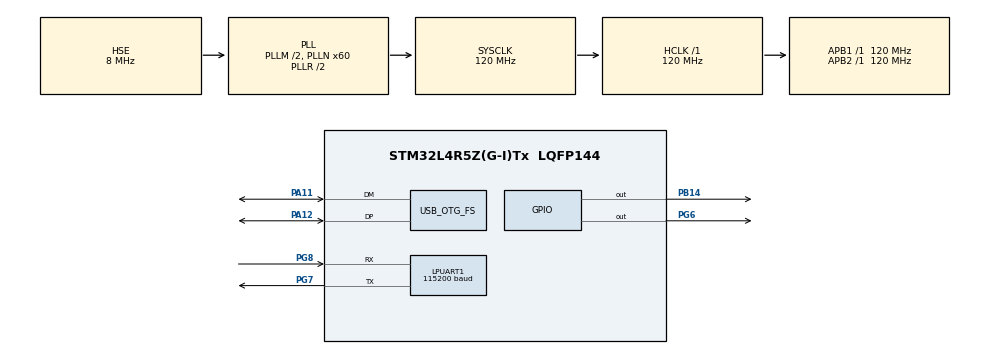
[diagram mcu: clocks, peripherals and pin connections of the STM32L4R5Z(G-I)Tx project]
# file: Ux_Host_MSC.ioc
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LPUART1.BaudRate=115200
LPUART1.WordLength=UART_WORDLENGTH_8B
Mcu.Family=STM32L4
Mcu.Name=STM32L4R5Z(G-I)Tx
Mcu.Package=LQFP144
NVIC.OTG_FS_IRQn=true\:7\:0\:true\:false\:true\:true\:true\:true\:true
NVIC.PriorityGroup=NVIC_PRIORITYGROUP_4
NVIC.TIM6_DAC_IRQn=true\:15\:0\:true\:false\:true\:false\:false\:true\:true
NVIC.TimeBase=TIM6_DAC_IRQn
NVIC.TimeBaseIP=TIM6
PA11.Mode=Host_Only
PA11.Signal=USB_OTG_FS_DM
PA12.Mode=Host_Only
PA12.Signal=USB_OTG_FS_DP
PB14.GPIO_Speed=GPIO_SPEED_FREQ_HIGH
PB14.Signal=GPIO_Output
PG6.Signal=GPIO_Output
PG7.Mode=Asynchronous
PG7.Signal=LPUART1_TX
PG8.Mode=Asynchronous
PG8.Signal=LPUART1_RX
PH0-OSC_IN\ (PH0).Mode=HSE-External-Clock-Source
PH0-OSC_IN\ (PH0).Signal=RCC_OSC_IN
ProjectManager.HeapSize=0x1000
ProjectManager.StackSize=0x1000
ProjectManager.TargetToolchain=Makefile
RCC.ADCFreq_Value=32000000
RCC.AHBFreq_Value=120000000
RCC.APB1Freq_Value=120000000
RCC.APB1TimFreq_Value=120000000
RCC.APB2Freq_Value=120000000
RCC.APB2TimFreq_Value=120000000
RCC.CK48CLockSelection=RCC_USBCLKSOURCE_HSI48
RCC.CortexFreq_Value=120000000
RCC.HCLKFreq_Value=120000000
RCC.HSE_VALUE=8000000
RCC.HSI48_VALUE=48000000
RCC.HSI_VALUE=16000000
RCC.LSE_VALUE=32768
RCC.MSIClockRange=RCC_MSIRANGE_11
RCC.MSI_VALUE=48000000
RCC.PLLM1=2
RCC.PLLN=60
RCC.PLLSourceVirtual=RCC_PLLSOURCE_HSE
RCC.PREFETCH_ENABLE=0
RCC.SYSCLKFreq_VALUE=120000000
RCC.SYSCLKSource=RCC_SYSCLKSOURCE_PLLCLK
RCC.USBFreq_Value=48000000
RCC.VCOOutputFreq_Value=240000000
STMicroelectronics.X-CUBE-AZRTOS-L4.2.0.0.FILEX_APPLICATION_THREAD_STACK_SIZE=1024
STMicroelectronics.X-CUBE-AZRTOS-L4.2.0.0.FX_APP_MEM_POOL_SIZE=1024 * 2
STMicroelectronics.X-CUBE-AZRTOS-L4.2.0.0.FileXCcFileOoSystemJjFileXJjCore=true
STMicroelectronics.X-CUBE-AZRTOS-L4.2.0.0.GENERATE_FILEX_INIT_CODE=false
STMicroelectronics.X-CUBE-AZRTOS-L4.2.0.0.ThreadXCcRTOSJjThreadXJjCore=true
STMicroelectronics.X-CUBE-AZRTOS-L4.2.0.0.USBXCcUSBJjUSBXJjCoreSystem=true
STMicroelectronics.X-CUBE-AZRTOS-L4.2.0.0.USBXCcUSBJjUSBXJjCoreUtilities=true
STMicroelectronics.X-CUBE-AZRTOS-L4.2.0.0.USBXCcUSBJjUSBXJjUXOoHostOoClassOoSTORAGE=true
STMicroelectronics.X-CUBE-AZRTOS-L4.2.0.0.USBXCcUSBJjUSBXJjUXOoHostOoControllers=true
STMicroelectronics.X-CUBE-AZRTOS-L4.2.0.0.USBXCcUSBJjUSBXJjUXOoHostOoCoreStack=true
STMicroelectronics.X-CUBE-AZRTOS-L4.2.0.0.USBX_HOST_SYS_SIZE=1024 * 22
STMicroelectronics.X-CUBE-AZRTOS-L4.2.0.0.UX_HOST_APP_MEM_POOL_SIZE=1024 * 25
STMicroelectronics.X-CUBE-AZRTOS-L4.2.0.0.UX_HOST_SIDE_ONLY=1
STMicroelectronics.X-CUBE-AZRTOS-L4.2.0.0_IsAnAzureRtosMw=true
USB_OTG_FS.VirtualMode=Host_Only
USB_OTG_FS.phy_itface=HCD_PHY_EMBEDDED
VP_STMicroelectronics.X-CUBE-AZRTOS-L4_VS_FileOoSystemJjFileX_6.2.0_2.0.0.Mode=FileOoSystemJjFileX
VP_STMicroelectronics.X-CUBE-AZRTOS-L4_VS_RTOSJjThreadX_6.2.0_2.0.0.Mode=RTOSJjThreadX
VP_STMicroelectronics.X-CUBE-AZRTOS-L4_VS_USBJjUSBX_6.2.0_2.0.0.Mode=USBJjUSBX
VP_SYS_VS_tim6.Mode=TIM6
board=NUCLEO-L4R5ZI

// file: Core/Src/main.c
/* USER CODE BEGIN Header */
/**
  ******************************************************************************
  * @file           : main.c
  * @brief          : Main program body
  ******************************************************************************
  * @attention
  *
  * Copyright (c) 2021 STMicroelectronics.
  * All rights reserved.
  *
  * This software is licensed under terms that can be found in the LICENSE file
  * in the root directory of this software component.
  * If no LICENSE file comes with this software, it is provided AS-IS.
  *
  ******************************************************************************
  */
/* USER CODE END Header */
#include "app_threadx.h"
#include "main.h"

/* USER CODE BEGIN Includes */
#include "stdio.h"
/* USER CODE END Includes */

UART_HandleTypeDef hlpuart1;

HCD_HandleTypeDef hhcd_USB_OTG_FS;

void SystemClock_Config(void);
static void MX_GPIO_Init(void);
static void MX_LPUART1_UART_Init(void);
/* USER CODE BEGIN PFP */
#if defined ( __GNUC__) && !defined(__clang__)
/* With GCC, small printf (option LD Linker->Libraries->Small printf
   set to 'Yes') calls __io_putchar() */
#define UART_DISPLAY int __io_putchar(int ch)
#else
#define UART_DISPLAY int fputc(int ch, FILE *f)
#endif /* __GNUC__ */
/* USER CODE END PFP */

int main(void)
{

  /* MCU Configuration--------------------------------------------------------*/

  /* Reset of all peripherals, Initializes the Flash interface and the Systick. */
  HAL_Init();

  /* Configure the system clock */
  SystemClock_Config();

  /* Initialize all configured peripherals */
  MX_GPIO_Init();
  MX_LPUART1_UART_Init();

  MX_ThreadX_Init();

  /* We should never get here as control is now taken by the scheduler */

  /* Infinite loop */
  while (1)
  {

  }
}

void SystemClock_Config(void)
{
  RCC_OscInitTypeDef RCC_OscInitStruct = {0};
  RCC_ClkInitTypeDef RCC_ClkInitStruct = {0};

  /** Configure the main internal regulator output voltage
  */
  if (HAL_PWREx_ControlVoltageScaling(PWR_REGULATOR_VOLTAGE_SCALE1_BOOST) != HAL_OK)
  {
    Error_Handler();
  }

  /** Initializes the RCC Oscillators according to the specified parameters
  * in the RCC_OscInitTypeDef structure.
  */
  RCC_OscInitStruct.OscillatorType = RCC_OSCILLATORTYPE_HSI48|RCC_OSCILLATORTYPE_HSE;
  RCC_OscInitStruct.HSEState = RCC_HSE_BYPASS;
  RCC_OscInitStruct.HSI48State = RCC_HSI48_ON;
  RCC_OscInitStruct.PLL.PLLState = RCC_PLL_ON;
  RCC_OscInitStruct.PLL.PLLSource = RCC_PLLSOURCE_HSE;
  RCC_OscInitStruct.PLL.PLLM = 2;
  RCC_OscInitStruct.PLL.PLLN = 60;
  RCC_OscInitStruct.PLL.PLLP = RCC_PLLP_DIV2;
  RCC_OscInitStruct.PLL.PLLQ = RCC_PLLQ_DIV2;
  RCC_OscInitStruct.PLL.PLLR = RCC_PLLR_DIV2;
  if (HAL_RCC_OscConfig(&RCC_OscInitStruct) != HAL_OK)
  {
    Error_Handler();
  }

  /** Initializes the CPU, AHB and APB buses clocks
  */
  RCC_ClkInitStruct.ClockType = RCC_CLOCKTYPE_HCLK|RCC_CLOCKTYPE_SYSCLK
                              |RCC_CLOCKTYPE_PCLK1|RCC_CLOCKTYPE_PCLK2;
  RCC_ClkInitStruct.SYSCLKSource = RCC_SYSCLKSOURCE_PLLCLK;
  RCC_ClkInitStruct.AHBCLKDivider = RCC_SYSCLK_DIV1;
  RCC_ClkInitStruct.APB1CLKDivider = RCC_HCLK_DIV1;
  RCC_ClkInitStruct.APB2CLKDivider = RCC_HCLK_DIV1;

  if (HAL_RCC_ClockConfig(&RCC_ClkInitStruct, FLASH_LATENCY_5) != HAL_OK)
  {
    Error_Handler();
  }
}

static void MX_LPUART1_UART_Init(void)
{

  hlpuart1.Instance = LPUART1;
  hlpuart1.Init.BaudRate = 115200;
  hlpuart1.Init.WordLength = UART_WORDLENGTH_8B;
  hlpuart1.Init.StopBits = UART_STOPBITS_1;
  hlpuart1.Init.Parity = UART_PARITY_NONE;
  hlpuart1.Init.Mode = UART_MODE_TX_RX;
  hlpuart1.Init.HwFlowCtl = UART_HWCONTROL_NONE;
  hlpuart1.Init.OneBitSampling = UART_ONE_BIT_SAMPLE_DISABLE;
  hlpuart1.Init.ClockPrescaler = UART_PRESCALER_DIV1;
  hlpuart1.AdvancedInit.AdvFeatureInit = UART_ADVFEATURE_NO_INIT;
  hlpuart1.FifoMode = UART_FIFOMODE_DISABLE;
  if (HAL_UART_Init(&hlpuart1) != HAL_OK)
  {
    Error_Handler();
  }
  if (HAL_UARTEx_SetTxFifoThreshold(&hlpuart1, UART_TXFIFO_THRESHOLD_1_8) != HAL_OK)
  {
    Error_Handler();
  }
  if (HAL_UARTEx_SetRxFifoThreshold(&hlpuart1, UART_RXFIFO_THRESHOLD_1_8) != HAL_OK)
  {
    Error_Handler();
  }
  if (HAL_UARTEx_DisableFifoMode(&hlpuart1) != HAL_OK)
  {
    Error_Handler();
  }

}

void MX_USB_OTG_FS_HCD_Init(void)
{

  hhcd_USB_OTG_FS.Instance = USB_OTG_FS;
  hhcd_USB_OTG_FS.Init.Host_channels = 12;
  hhcd_USB_OTG_FS.Init.speed = USB_OTG_SPEED_FULL;
  hhcd_USB_OTG_FS.Init.dma_enable = DISABLE;
  hhcd_USB_OTG_FS.Init.phy_itface = HCD_PHY_EMBEDDED;
  hhcd_USB_OTG_FS.Init.Sof_enable = DISABLE;
  hhcd_USB_OTG_FS.Init.vbus_sensing_enable = DISABLE;
  if (HAL_HCD_Init(&hhcd_USB_OTG_FS) != HAL_OK)
  {
    Error_Handler();
  }

}

static void MX_GPIO_Init(void)
{
  GPIO_InitTypeDef GPIO_InitStruct = {0};

  /* GPIO Ports Clock Enable */
  __HAL_RCC_GPIOH_CLK_ENABLE();
  __HAL_RCC_GPIOB_CLK_ENABLE();
  __HAL_RCC_GPIOG_CLK_ENABLE();
  HAL_PWREx_EnableVddIO2();
  __HAL_RCC_GPIOA_CLK_ENABLE();

  /*Configure GPIO pin Output Level */
  HAL_GPIO_WritePin(GPIOB, GPIO_PIN_14, GPIO_PIN_RESET);

  /*Configure GPIO pin Output Level */
  HAL_GPIO_WritePin(GPIOG, GPIO_PIN_6, GPIO_PIN_RESET);

  /*Configure GPIO pin : PB14 */
  GPIO_InitStruct.Pin = GPIO_PIN_14;
  GPIO_InitStruct.Mode = GPIO_MODE_OUTPUT_PP;
  GPIO_InitStruct.Pull = GPIO_NOPULL;
  GPIO_InitStruct.Speed = GPIO_SPEED_FREQ_HIGH;
  HAL_GPIO_Init(GPIOB, &GPIO_InitStruct);

  /*Configure GPIO pin : PG6 */
  GPIO_InitStruct.Pin = GPIO_PIN_6;
  GPIO_InitStruct.Mode = GPIO_MODE_OUTPUT_PP;
  GPIO_InitStruct.Pull = GPIO_NOPULL;
  GPIO_InitStruct.Speed = GPIO_SPEED_FREQ_LOW;
  HAL_GPIO_Init(GPIOG, &GPIO_InitStruct);

}

/* USER CODE BEGIN 4 */
/**
  * @brief  Retargets the C library printf function to the USART.
  * @param  None
  * @retval None
  */
UART_DISPLAY
{
  /* Place your implementation of fputc here */
  /* e.g. write a character to the EVAL_COM1 and Loop until the end of transmission */
  HAL_UART_Transmit(&hlpuart1, (uint8_t *)&ch, 1, 0xFFFF);

  return ch;
}
/* USER CODE END 4 */

void HAL_TIM_PeriodElapsedCallback(TIM_HandleTypeDef *htim)
{
  if (htim->Instance == TIM6) {
    HAL_IncTick();
  }
}

void Error_Handler(void)
{
  __disable_irq();
  while (1)
  {
  }
}
